# SKEAZ1284 register map
Vendor: Freescale Semiconductor, Inc.; Series: Kinetis_EA; File version: 1.6
CPU: CM0PLUS r0p0, little endian, no MPU, no FPU, VTOR, 2 interrupt priority bits
Registers are 8-bit, read-write, reset 0x0 unless marked. A register's access mark holds for its fields unless they carry their own. Offsets are from the block's base; [hi:lo] are bit positions; {n}, {i} and the like mark numbered series.

## PWT — Pulse Width Timer
Base 0x40033000; register names take the prefix PWT_
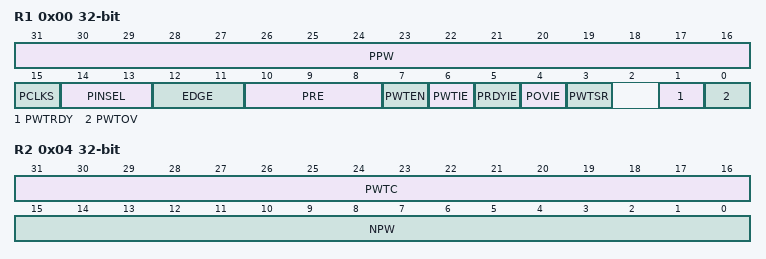
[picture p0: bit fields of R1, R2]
0x00 R1 32-bit — Pulse Width Timer Register 1
  [31:16] PPW ro — Positive Pulse Width
  [15] PCLKS — PWT Clock Source Selection
    0=Bus clock is selected as the clock source of PWT counter; 1=Alternative clock is selected as the clock source of PWT counter
  [14:13] PINSEL — PWT Pulse Inputs Selection
    0=PWTIN[0] is enabled; 1=PWTIN[1] is enabled; 2=PWTIN[2] enabled; 3=PWTIN[3] enabled
  [12:11] EDGE — PWT Input Edge Sensitivity
    0=The first falling-edge starts the pulse width measurement, and on all the subsequent falling edges, the pulse width is captured; 1=The first rising edge starts the pulse width measurement, and on all the subsequent rising and falling edges, the pulse width is captured; 2=The first falling edge starts the pulse width measurement, and on all the subsequent rising and falling edges, the pulse width is captured; 3=The first-rising edge starts the pulse width measurement, and on all the subsequent rising edges, the pulse width is captured
  [10:8] PRE — PWT Clock Prescaler (CLKPRE) Setting
    0=Clock divided by 1; 1=Clock divided by 2; 2=Clock divided by 4; 3=Clock divided by 8; 4=Clock divided by 16; 5=Clock divided by 32; 6=Clock divided by 64; 7=Clock divided by 128
  [7] PWTEN — PWT Module Enable
    0=The PWT is disabled; 1=The PWT is enabled
  [6] PWTIE — PWT Module Interrupt Enable
    0=Disables the PWT to generate interrupt; 1=Enables the PWT to generate interrupt
  [5] PRDYIE — PWT Pulse Width Data Ready Interrupt Enable
    0=Disable PWT to generate interrupt when PWTRDY is set; 1=Enable PWT to generate interrupt when PWTRDY is set
  [4] POVIE — PWT Counter Overflow Interrupt Enable
    0=Disable PWT to generate interrupt when PWTOV is set; 1=Enable PWT to generate interrupt when PWTOV is set
  [3] PWTSR wo — PWT Soft Reset
    0=No action taken; 1=Writing 1 to this field will perform soft reset to PWT
  [1] PWTRDY — PWT Pulse Width Valid
    0=PWT pulse width register(s) is not up-to-date; 1=PWT pulse width register(s) has been updated
  [0] PWTOV — PWT Counter Overflow
    0=PWT counter no overflow; 1=PWT counter runs from 0xFFFF to 0x0000
0x04 R2 32-bit ro — Pulse Width Timer Register 2
  [31:16] PWTC — PWT Counter. It is suggested to use half-word (16-bit) or word (32-bit) to read out this value.
  [15:0] NPW — Negative Pulse Width. It is suggested to use half-word (16-bit) or word (32-bit) to read out this value.

## PIT — Periodic Interrupt Timer
Base 0x40037000; register names take the prefix PIT_
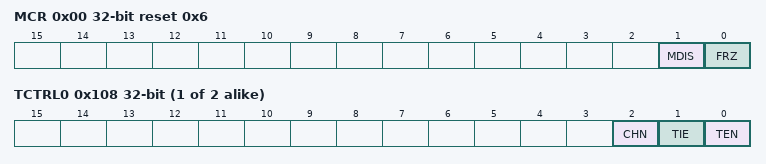
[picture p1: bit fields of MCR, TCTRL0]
0x00 MCR 32-bit reset 0x6 — PIT Module Control Register
  [1] MDIS — Module Disable - (PIT section)
    0=Clock for standard PIT timers is enabled; 1=Clock for standard PIT timers is disabled
  [0] FRZ — Freeze
    0=Timers continue to run in Debug mode; 1=Timers are stopped in Debug mode
{0x100+0x10*i} LDVAL{i} (i=0..1) 32-bit — Timer Load Value Register
  [31:0] TSV — Timer Start Value
{0x104+0x10*i} CVAL{i} (i=0..1) 32-bit ro — Current Timer Value Register
  [31:0] TVL — Current Timer Value
{0x108+0x10*i} TCTRL{i} (i=0..1) 32-bit — Timer Control Register
  [2] CHN — Chain Mode
    0=Timer is not chained; 1=Timer is chained to previous timer. For example, for Channel 2, if this field is set, Timer 2 is chained to Timer 1.
  [1] TIE — Timer Interrupt Enable
    0=Interrupt requests from Timer n are disabled; 1=Interrupt will be requested whenever TIF is set
  [0] TEN — Timer Enable
    0=Timer n is disabled; 1=Timer n is enabled
{0x10C+0x10*i} TFLG{i} (i=0..1) 32-bit — Timer Flag Register
  [0] TIF — Timer Interrupt Flag
    0=Timeout has not yet occurred; 1=Timeout has occurred
